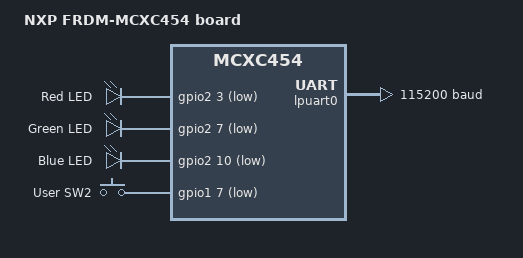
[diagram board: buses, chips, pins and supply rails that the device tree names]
/*
 * Copyright 2026 NXP
 *
 * SPDX-License-Identifier: Apache-2.0
 */

/dts-v1/;

#include <nxp/mcx/mcxc/nxp_mcxc454.dtsi>
#include "frdm_mcxc454-pinctrl.dtsi"
#include <zephyr/dt-bindings/input/input-event-codes.h>

/ {
	model = "NXP FRDM-MCXC454 board";
	compatible = "nxp,mcxc454", "nxp,mcx";

	aliases {
		led0 = &red_led;
		led1 = &green_led;
		led2 = &blue_led;
		sw0 = &user_button_2;
	};

	chosen {
		zephyr,sram = &sram0;
		zephyr,flash = &flash;
		zephyr,flash-controller = &fmu;
		zephyr,console = &lpuart0;
		zephyr,shell-uart = &lpuart0;
	};

	leds {
		compatible = "gpio-leds";

		red_led: led_0 {
			gpios = <&gpio2 3 GPIO_ACTIVE_LOW>;
			label = "Red LED";
		};

		green_led: led_1 {
			gpios = <&gpio2 7 GPIO_ACTIVE_LOW>;
			label = "Green LED";
		};

		blue_led: led_2 {
			gpios = <&gpio2 10 GPIO_ACTIVE_LOW>;
			label = "Blue LED";
		};
	};

	gpio_keys {
		compatible = "gpio-keys";

		user_button_2: button_2 {
			label = "User SW2";
			gpios = <&gpio1 7 GPIO_ACTIVE_LOW>;
			zephyr,code = <INPUT_KEY_0>;
		};
	};
};

&cpu0 {
	clock-frequency = <12000000>;
};

&gpio1 {
	status = "okay";
};

&gpio2 {
	status = "okay";
};

&lpuart0 {
	status = "okay";
	current-speed = <115200>;
	pinctrl-0 = <&pinmux_lpuart0>;
	pinctrl-names = "default";
};
